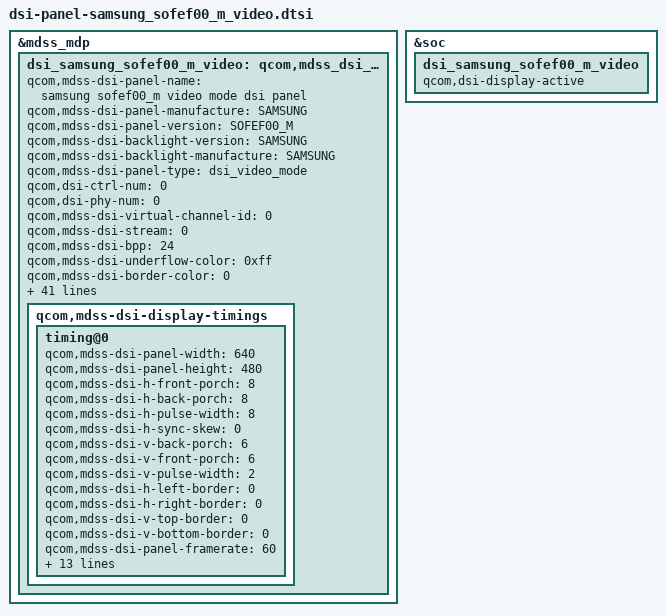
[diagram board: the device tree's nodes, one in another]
/* Copyright (c) 2015-2017, The Linux Foundation. All rights reserved.
 *
 * This program is free software; you can redistribute it and/or modify
 * it under the terms of the GNU General Public License version 2 and
 * only version 2 as published by the Free Software Foundation.
 *
 * This program is distributed in the hope that it will be useful,
 * but WITHOUT ANY WARRANTY; without even the implied warranty of
 * MERCHANTABILITY or FITNESS FOR A PARTICULAR PURPOSE.  See the
 * GNU General Public License for more details.
 */

&mdss_mdp {
	dsi_samsung_sofef00_m_video: qcom,mdss_dsi_samsung_sofef00_m_video {
		qcom,mdss-dsi-panel-name =
		"samsung sofef00_m video mode dsi panel";
		qcom,mdss-dsi-panel-manufacture = "SAMSUNG";
		qcom,mdss-dsi-panel-version = "SOFEF00_M";
		qcom,mdss-dsi-backlight-version = "SAMSUNG";
		qcom,mdss-dsi-backlight-manufacture = "SAMSUNG";
		qcom,mdss-dsi-panel-type = "dsi_video_mode";

		qcom,dsi-ctrl-num = <0>;
		qcom,dsi-phy-num = <0>;

		qcom,mdss-dsi-virtual-channel-id = <0>;
		qcom,mdss-dsi-stream = <0>;
		qcom,mdss-dsi-bpp = <24>;
		qcom,mdss-dsi-underflow-color = <0xff>;
		qcom,mdss-dsi-border-color = <0>;
		qcom,mdss-dsi-panel-peak-brightness = <4200000>;
		qcom,mdss-dsi-traffic-mode = "non_burst_sync_event";
		qcom,mdss-dsi-bllp-eof-power-mode;
		qcom,mdss-dsi-bllp-power-mode;
		qcom,mdss-dsi-lane-0-state;
		qcom,mdss-dsi-lane-1-state;
		qcom,mdss-dsi-lane-2-state;
		qcom,mdss-dsi-lane-3-state;
		qcom,mdss-dsi-t-clk-post = <0x04>;
		qcom,mdss-dsi-t-clk-pre = <0x1b>;
		qcom,mdss-dsi-dma-trigger = "trigger_sw";
		qcom,mdss-dsi-mdp-trigger = "none";
		qcom,mdss-dsi-reset-sequence = <1 0>, <0 0>, <1 0>;
		qcom,panel-ack-disabled;
		qcom,mdss-dsi-bl-min-level = <1>;
		qcom,mdss-dsi-bl-max-level = <1023>;
		qcom,mdss-brightness-default-val = <200>;
		qcom,mdss-brightness-max-level = <1023>;
		qcom,mdss-pan-physical-width-dimension = <68>;
		qcom,mdss-pan-physical-height-dimension = <145>;
		qcom,mdss-dsi-init-delay-us = <1000>;
		qcom,mdss-dsi-lp11-init;
		qcom,mdss-dsi-wr-mem-start = <0x2c>;
		qcom,mdss-dsi-wr-mem-continue = <0x3c>;
		qcom,mdss-bl-high2bit;
		/* HDR Setting */
		qcom,mdss-dsi-panel-hdr-enabled;
		qcom,mdss-dsi-panel-hdr-color-primaries = <15635 16450 34000 16000 13250 34500 7500 3000>;
		qcom,mdss-dsi-panel-average-brightness = <2000000>;
		qcom,mdss-dsi-panel-blackness-level = <2000>;
		qcom,mdss-dsi-display-timings {
			timing@0 {
				qcom,mdss-dsi-panel-width = <640>;
				qcom,mdss-dsi-panel-height = <480>;
				qcom,mdss-dsi-h-front-porch = <8>;
				qcom,mdss-dsi-h-back-porch = <8>;
				qcom,mdss-dsi-h-pulse-width = <8>;
				qcom,mdss-dsi-h-sync-skew = <0>;
				qcom,mdss-dsi-v-back-porch = <6>;
				qcom,mdss-dsi-v-front-porch = <6>;
				qcom,mdss-dsi-v-pulse-width = <2>;
				qcom,mdss-dsi-h-left-border = <0>;
				qcom,mdss-dsi-h-right-border = <0>;
				qcom,mdss-dsi-v-top-border = <0>;
				qcom,mdss-dsi-v-bottom-border = <0>;
				qcom,mdss-dsi-panel-framerate = <60>;
				qcom,mdss-dsi-panel-timings =
					[00 00 00 00 00 00 00 00 00 00 00 00];
				qcom,mdss-dsi-on-command =
					[32 01 00 00 00 00 02 00 00];
				qcom,mdss-dsi-off-command =
					[22 01 00 00 00 00 02 00 00];
				qcom,mdss-dsi-on-command-state = "dsi_lp_mode";
				qcom,mdss-dsi-off-command-state = "dsi_lp_mode";
				qcom,mdss-dsi-h-sync-pulse = <0>;
			};
		};
	};
};
&dsi_samsung_sofef00_m_video {
	qcom,dsi-ctrl-num = <0>;
	qcom,dsi-phy-num = <0>;
	//qcom,dsi-select-clocks = "src_byte_clk0", "src_pixel_clk0";
	qcom,panel-supply-entries = <&dsi_panel_pwr_supply>;
	qcom,mdss-dsi-bl-pmic-control-type = "bl_ctrl_dcs";
	qcom,platform-te-gpio = <&tlmm 66 0>;
	qcom,platform-reset-gpio = <&tlmm 75 0>;
};
&soc {
	dsi_samsung_sofef00_m_video {
		qcom,dsi-display-active;
	};
};
&dsi_samsung_sofef00_m_video {
	qcom,ulps-enabled;
	qcom,dsi-select-clocks = "mux_byte_clk0", "mux_pixel_clk0","pw_bb_clk2";
	qcom,mdss-dsi-display-timings {
		timing@0 {
			qcom,mdss-dsi-panel-phy-timings = [00 1c 08 07 23 22 07
				07 05 02 04 00 18 17];
			qcom,display-topology = <1 0 1>,
						<2 0 1>;
			qcom,default-topology-index = <0>;
		};
	};
};
